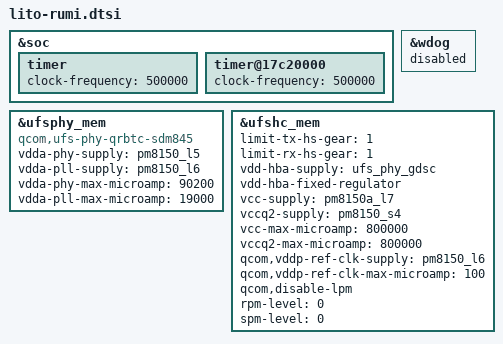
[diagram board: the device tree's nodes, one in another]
// SPDX-License-Identifier: GPL-2.0-only
/*
 * Copyright  (c) 2018 , The Linux Foundation. All rights reserved.
 */

&soc {
	timer {
		clock-frequency = <500000>;
	};

	timer@17c20000 {
		clock-frequency = <500000>;
	};
};

&wdog {
	status = "disabled";
};

&ufsphy_mem {
	compatible = "qcom,ufs-phy-qrbtc-sdm845";

	vdda-phy-supply = <&pm8150_l5>;
	vdda-pll-supply = <&pm8150_l6>;
	vdda-phy-max-microamp = <90200>;
	vdda-pll-max-microamp = <19000>;

	status = "ok";
};

&ufshc_mem {
	limit-tx-hs-gear = <1>;
	limit-rx-hs-gear = <1>;

	vdd-hba-supply = <&ufs_phy_gdsc>;
	vdd-hba-fixed-regulator;
	vcc-supply = <&pm8150a_l7>;
	vccq2-supply = <&pm8150_s4>;
	vcc-max-microamp = <800000>;
	vccq2-max-microamp = <800000>;

	qcom,vddp-ref-clk-supply = <&pm8150_l6>;
	qcom,vddp-ref-clk-max-microamp = <100>;

	qcom,disable-lpm;
	rpm-level = <0>;
	spm-level = <0>;
	status = "ok";
};
